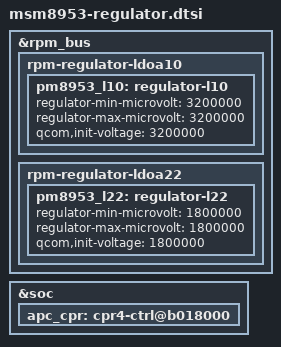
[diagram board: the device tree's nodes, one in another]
/*
 * Copyright (c) 2015-2016, The Linux Foundation. All rights reserved.
 *
 * This program is free software; you can redistribute it and/or modify
 * it under the terms of the GNU General Public License version 2 and
 * only version 2 as published by the Free Software Foundation.
 *
 * This program is distributed in the hope that it will be useful,
 * but WITHOUT ANY WARRANTY; without even the implied warranty of
 * MERCHANTABILITY or FITNESS FOR A PARTICULAR PURPOSE.  See the
 * GNU General Public License for more details.
 */

#include <dt-bindings/interrupt-controller/arm-gic.h>

&rpm_bus {

	rpm-regulator-ldoa10 {
		pm8953_l10: regulator-l10 {
			regulator-min-microvolt = <3200000>;
			regulator-max-microvolt = <3200000>;
			qcom,init-voltage = <3200000>;
		};
	};

	rpm-regulator-ldoa22 {
		pm8953_l22: regulator-l22 {
			regulator-min-microvolt = <1800000>;
			regulator-max-microvolt = <1800000>;
			qcom,init-voltage = <1800000>;
		};
	};

};

&soc {
	apc_cpr: cpr4-ctrl@b018000 {
		/delete-property/ qcom,cpr-panic-reg-addr-list;
		/delete-property/ qcom,cpr-panic-reg-name-list;

	};

};
